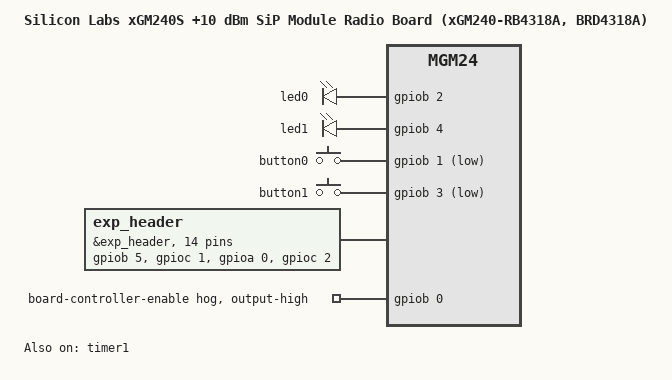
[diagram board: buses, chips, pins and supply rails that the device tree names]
/*
 * Copyright (c) 2026 Silicon Laboratories Inc.
 *
 * SPDX-License-Identifier: Apache-2.0
 */

/dts-v1/;
#include <silabs/xg24/mgm240sd22vna.dtsi>
#include "xg24_common.dtsi"
#include "xgm240_rb4318a-pinctrl.dtsi"

/ {
	model = "Silicon Labs xGM240S +10 dBm SiP Module Radio Board (xGM240-RB4318A, BRD4318A)";
	compatible = "silabs,xgm240_rb4318a", "silabs,mgm24";
};

&led0 {
	gpios = <&gpiob 2 GPIO_ACTIVE_HIGH>;
};

&led1 {
	gpios = <&gpiob 4 GPIO_ACTIVE_HIGH>;
};

&pwm_led0 {
	pwms = <&timer0_pwm 0 PWM_MSEC(20) PWM_POLARITY_NORMAL>;
};

&pwm_led1 {
	pwms = <&timer0_pwm 1 PWM_MSEC(20) PWM_POLARITY_NORMAL>;
};

&button0 {
	gpios = <&gpiob 1 GPIO_ACTIVE_LOW>;
};

&button1 {
	gpios = <&gpiob 3 GPIO_ACTIVE_LOW>;
};

&sensor_enable {
	enable-gpios = <&gpiod 3 GPIO_ACTIVE_HIGH>;
};

&exp_header {
	gpio-map = <3 0 &gpiob 5 0>,
		   <4 0 &gpioc 1 0>,
		   <5 0 &gpioa 0 0>,
		   <6 0 &gpioc 2 0>,
		   <7 0 &gpioa 5 0>,
		   <8 0 &gpioc 3 0>,
		   <9 0 &gpiod 2 0>,
		   <10 0 &gpioc 0 0>,
		   <11 0 &gpioa 6 0>,
		   <12 0 &gpioa 8 0>,
		   <13 0 &gpioa 7 0>,
		   <14 0 &gpioa 9 0>,
		   <15 0 &gpioc 5 0>,
		   <16 0 &gpioc 7 0>;
};

&lfxo {
	ctune = <63>;
};

&eusart1 {
	cs-gpios = <&gpioc 8 GPIO_ACTIVE_HIGH>, <&gpioc 4 GPIO_ACTIVE_LOW>;
};

&ls0xx_ls013b7dh03 {
	disp-en-gpios = <&gpioc 9 GPIO_ACTIVE_HIGH>;
	extcomin-gpios = <&gpioc 6 GPIO_ACTIVE_HIGH>;
};

&timer1 {
	status = "okay";

	timer1_counter: counter {
		status = "okay";
	};
};

&gpiob {
	board-controller-enable {
		gpio-hog;
		gpios = <0 GPIO_ACTIVE_HIGH>;
		output-high;
	};
};
